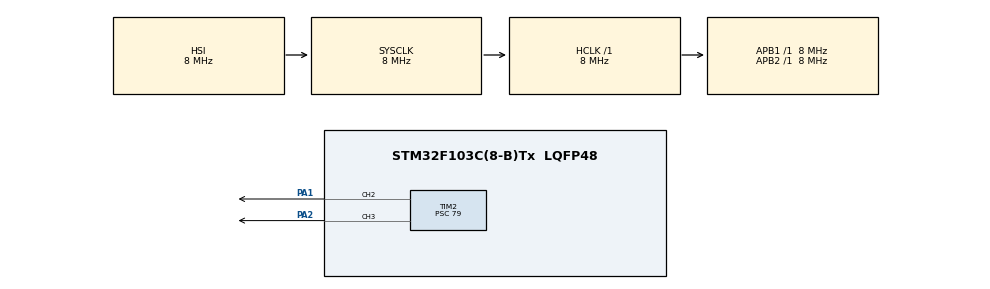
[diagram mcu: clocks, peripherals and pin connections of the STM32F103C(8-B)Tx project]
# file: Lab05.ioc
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Mcu.Family=STM32F1
Mcu.Name=STM32F103C(8-B)Tx
Mcu.Package=LQFP48
NVIC.PriorityGroup=NVIC_PRIORITYGROUP_4
NVIC.TIM3_IRQn=true\:0\:0\:false\:true\:true\:1\:true\:true\:true
NVIC.TIM4_IRQn=true\:0\:0\:false\:true\:true\:2\:true\:true\:true
PA1.Signal=S_TIM2_CH2
PA2.Signal=S_TIM2_CH3
ProjectManager.HeapSize=0x200
ProjectManager.StackSize=0x400
ProjectManager.TargetToolchain=STM32CubeIDE
RCC.AHBFreq_Value=8000000
RCC.APB1Freq_Value=8000000
RCC.APB1TimFreq_Value=8000000
RCC.APB2Freq_Value=8000000
RCC.APB2TimFreq_Value=8000000
RCC.HCLKFreq_Value=8000000
RCC.PLLMUL=RCC_PLL_MUL9
RCC.SYSCLKFreq_VALUE=8000000
RCC.USBFreq_Value=36000000
SH.S_TIM2_CH2.0=TIM2_CH2,PWM Generation2 CH2
SH.S_TIM2_CH3.0=TIM2_CH3,PWM Generation3 CH3
TIM2.Channel-PWM\ Generation2\ CH2=TIM_CHANNEL_2
TIM2.Channel-PWM\ Generation3\ CH3=TIM_CHANNEL_3
TIM2.Period=1999
TIM2.Prescaler=79
TIM2.Pulse-PWM\ Generation2\ CH2=99
TIM2.Pulse-PWM\ Generation3\ CH3=149
TIM3.Period=30
TIM3.Prescaler=7999
TIM4.Period=10
TIM4.Prescaler=7999
VP_TIM3_VS_ClockSourceINT.Mode=Internal
VP_TIM4_VS_ClockSourceINT.Mode=Internal
board=custom

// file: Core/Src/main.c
/* USER CODE BEGIN Header */
/**
  ******************************************************************************
  * @file           : main.c
  * @brief          : Main program body
  ******************************************************************************
  * @attention
  *
  * Copyright (c) 2023 STMicroelectronics.
  * All rights reserved.
  *
  * This software is licensed under terms that can be found in the LICENSE file
  * in the root directory of this software component.
  * If no LICENSE file comes with this software, it is provided AS-IS.
  *
  ******************************************************************************
  */
/* USER CODE END Header */
#include "main.h"
#include "tim.h"
#include "gpio.h"

/* USER CODE BEGIN PD */
//На залізі необхідно мін 50 макс 250 для тривалості імпульсу від 0,5 до 2,5 мс
//Для Proteus треба змеінити діапазон мін та макс(???)
#define MIN_PULSE_WIDTH_S1 95
#define MAX_PULSE_WIDTH_S1 150
#define MIN_PULSE_WIDTH_S2 149
#define MAX_PULSE_WIDTH_S2 210
/* USER CODE END PD */

/* USER CODE BEGIN PV */
 int myPulsePWM1, myPulsePWM2;
/* USER CODE END PV */

void SystemClock_Config(void);
static void MX_NVIC_Init(void);

int main(void)
{

  /* MCU Configuration--------------------------------------------------------*/

  /* Reset of all peripherals, Initializes the Flash interface and the Systick. */
  HAL_Init();

  /* Configure the system clock */
  SystemClock_Config();

  /* Initialize all configured peripherals */
  MX_GPIO_Init();
  MX_TIM2_Init();
  MX_TIM3_Init();
  MX_TIM4_Init();

  /* Initialize interrupts */
  MX_NVIC_Init();
  /* USER CODE BEGIN 2 */
  HAL_TIM_Base_Start_IT(&htim3);
  HAL_TIM_Base_Start_IT(&htim4);
  HAL_TIM_PWM_Start(&htim2, TIM_CHANNEL_2);
  HAL_TIM_PWM_Start(&htim2, TIM_CHANNEL_3);
  HAL_TIM_PWM_Start(&htim2, TIM_CHANNEL_4);

  /* USER CODE END 2 */

  /* Infinite loop */
  while (1)
  {
  }

}

void SystemClock_Config(void)
{
  RCC_OscInitTypeDef RCC_OscInitStruct = {0};
  RCC_ClkInitTypeDef RCC_ClkInitStruct = {0};

  /** Initializes the RCC Oscillators according to the specified parameters
  * in the RCC_OscInitTypeDef structure.
  */
  RCC_OscInitStruct.OscillatorType = RCC_OSCILLATORTYPE_HSI;
  RCC_OscInitStruct.HSIState = RCC_HSI_ON;
  RCC_OscInitStruct.HSICalibrationValue = RCC_HSICALIBRATION_DEFAULT;
  RCC_OscInitStruct.PLL.PLLState = RCC_PLL_NONE;
  if (HAL_RCC_OscConfig(&RCC_OscInitStruct) != HAL_OK)
  {
    Error_Handler();
  }

  /** Initializes the CPU, AHB and APB buses clocks
  */
  RCC_ClkInitStruct.ClockType = RCC_CLOCKTYPE_HCLK|RCC_CLOCKTYPE_SYSCLK
                              |RCC_CLOCKTYPE_PCLK1|RCC_CLOCKTYPE_PCLK2;
  RCC_ClkInitStruct.SYSCLKSource = RCC_SYSCLKSOURCE_HSI;
  RCC_ClkInitStruct.AHBCLKDivider = RCC_SYSCLK_DIV1;
  RCC_ClkInitStruct.APB1CLKDivider = RCC_HCLK_DIV1;
  RCC_ClkInitStruct.APB2CLKDivider = RCC_HCLK_DIV1;

  if (HAL_RCC_ClockConfig(&RCC_ClkInitStruct, FLASH_LATENCY_0) != HAL_OK)
  {
    Error_Handler();
  }
}

/**
  * @brief NVIC Configuration.
  * @retval None
  */
static void MX_NVIC_Init(void)
{
  /* TIM3_IRQn interrupt configuration */
  HAL_NVIC_SetPriority(TIM3_IRQn, 0, 0);
  HAL_NVIC_EnableIRQ(TIM3_IRQn);
  /* TIM4_IRQn interrupt configuration */
  HAL_NVIC_SetPriority(TIM4_IRQn, 0, 0);
  HAL_NVIC_EnableIRQ(TIM4_IRQn);
}

/* USER CODE BEGIN 4 */
void HAL_TIM_PeriodElapsedCallback(TIM_HandleTypeDef *htim)
{
	if(htim->Instance == TIM3)
	{
		  static uint8_t pulse_width = MIN_PULSE_WIDTH_S1;
		  static uint8_t direction = 1;

		  /* Зміна тривалості імпульсу */
		  if (direction == 1)
		  	  {
			  	  pulse_width++;
			  	  if (pulse_width == MAX_PULSE_WIDTH_S1)
		    			{
			  		  	  	  direction = 0;
		    			}
		  	  } else {
		    pulse_width--;
		    if (pulse_width == MIN_PULSE_WIDTH_S1)
		    {
		      direction = 1;
		    }
		  	  	  }
		  __HAL_TIM_SET_COMPARE(&htim2, TIM_CHANNEL_2, pulse_width);
	}
	if(htim->Instance == TIM4)
	{
		  static uint8_t pulse_width = MIN_PULSE_WIDTH_S2;
		  static uint8_t direction = 1;

		  /* Зміна тривалості імпульсу */
		  if (direction == 1)
		  	  {
			  	  pulse_width++;
			  	  if (pulse_width == MAX_PULSE_WIDTH_S2)
		    			{
			  		  	  	  direction = 0;
		    			}
		  	  } else {
		    pulse_width--;
		    if (pulse_width == MIN_PULSE_WIDTH_S2)
		    {
		      direction = 1;
		    }
		  	  	  }
		  __HAL_TIM_SET_COMPARE(&htim2, TIM_CHANNEL_3, pulse_width);
	}

}

/* USER CODE END 4 */

void Error_Handler(void)
{
  /* USER CODE BEGIN Error_Handler_Debug */
//  /* User can add his own implementation to report the HAL error return state */
//  __disable_irq();
//  while (1)
//  {
//  }
  /* USER CODE END Error_Handler_Debug */
}
